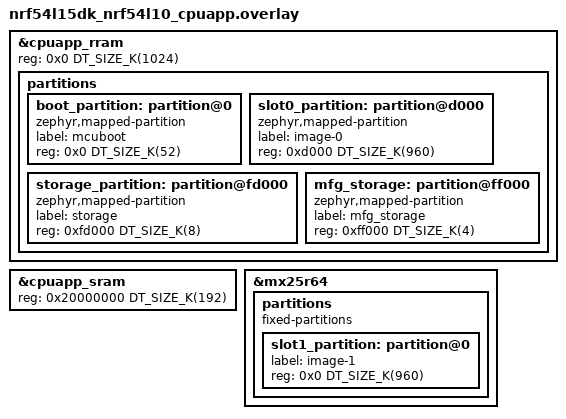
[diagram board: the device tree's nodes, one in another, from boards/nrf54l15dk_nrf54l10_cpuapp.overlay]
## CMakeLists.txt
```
#
# Copyright (c) 2022 Nordic Semiconductor ASA
#
# SPDX-License-Identifier: LicenseRef-Nordic-5-Clause
#

cmake_minimum_required(VERSION 3.20.0)

find_package(Zephyr REQUIRED HINTS $ENV{ZEPHYR_BASE})
project(sidewalk_mfg_test)

# add test file
FILE(GLOB app_sources src/*.c)
target_sources(app PRIVATE ${app_sources})
target_include_directories(app PRIVATE .)
target_link_options(app PRIVATE "LINKER:--start-group")
target_link_libraries(app PRIVATE sidewalk_pal)
target_link_options(app PRIVATE "LINKER:--end-group")
```

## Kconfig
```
#
# Copyright (c) 2022 Nordic Semiconductor ASA
#
# SPDX-License-Identifier: LicenseRef-Nordic-5-Clause
#
config SIDEWALK_BUILD
	default y

config SIDEWALK_USE_PREBUILT_LIBRARIES
	default y


config SIDEWALK_MFG_STORAGE
	default y

config SIDEWALK_MFG_ALLOW_WRITE
	default y

config SIDEWALK_TLV
	default y

config SIDEWALK_TLV_FLASH
	default y

config SIDEWALK_TLV_RAM
	default y

config SIDEWALK_LOG
	default y
	imply LOG

config SIDEWALK_LOG_LEVEL
	default 0

config SIDEWALK_LOG_MSG_LENGTH_MAX
	default 80


source "Kconfig.zephyr"
source "${ZEPHYR_BASE}/../sidewalk/Kconfig.dependencies"
```

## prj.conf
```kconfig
#
# Copyright (c) 2022 Nordic Semiconductor ASA
#
# SPDX-License-Identifier: LicenseRef-Nordic-5-Clause
#
CONFIG_ZTEST=y
CONFIG_MAIN_THREAD_PRIORITY=14
CONFIG_PARTITION_MANAGER_ENABLED=n
```

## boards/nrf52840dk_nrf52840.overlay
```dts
/*
 * Copyright (c) 2024 Nordic Semiconductor ASA
 *
 * SPDX-License-Identifier: LicenseRef-Nordic-5-Clause
 */

#include <state_notifier_aliases.dtsi>

#include <nrf52840_partitions.dtsi>
```

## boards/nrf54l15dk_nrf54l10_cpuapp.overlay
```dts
/*
 * Copyright (c) 2024 Nordic Semiconductor ASA
 *
 * SPDX-License-Identifier: LicenseRef-Nordic-5-Clause
 */

&cpuapp_rram {
	reg = <0x0 DT_SIZE_K(1024)>;
};

&cpuapp_sram {
	reg = <0x20000000 DT_SIZE_K(192)>;
	ranges = <0x0 0x20000000 DT_SIZE_K(192)>;
};

&mx25r64 {
	status = "okay";
};

/delete-node/ &boot_partition;
/delete-node/ &slot0_partition;
/delete-node/ &slot1_partition;
/delete-node/ &storage_partition;

&cpuapp_rram {
	partitions {
		ranges;
		#address-cells = <1>;
		#size-cells = <1>;

		boot_partition: partition@0 {
			compatible = "zephyr,mapped-partition";
			label = "mcuboot";
			reg = <0x0 DT_SIZE_K(52)>;
		};

		slot0_partition: partition@d000 {
			compatible = "zephyr,mapped-partition";
			label = "image-0";
			reg = <0xd000 DT_SIZE_K(960)>;
		};

		storage_partition: partition@fd000 {
			compatible = "zephyr,mapped-partition";
			label = "storage";
			reg = <0xfd000 DT_SIZE_K(8)>;
		};

		mfg_storage: partition@ff000 {
			compatible = "zephyr,mapped-partition";
			label = "mfg_storage";
			reg = <0xff000 DT_SIZE_K(4)>;
		};
	};
};

&mx25r64 {
	partitions {
		compatible = "fixed-partitions";
		#address-cells = <1>;
		#size-cells = <1>;

		slot1_partition: partition@0 {
			label = "image-1";
			reg = <0x0 DT_SIZE_K(960)>;
		};
	};
};
```

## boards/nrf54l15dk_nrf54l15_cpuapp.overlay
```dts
/*
 * Copyright (c) 2024 Nordic Semiconductor ASA
 *
 * SPDX-License-Identifier: LicenseRef-Nordic-5-Clause
 */

#include <state_notifier_aliases.dtsi>

#include <nrf54l15_cpuapp_partitions.dtsi>
```

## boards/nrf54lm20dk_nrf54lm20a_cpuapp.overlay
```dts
/*
 * Copyright (c) 2025 Nordic Semiconductor ASA
 *
 * SPDX-License-Identifier: LicenseRef-Nordic-5-Clause
 */

#include <nrf54lm20_cpuapp_partitions.dtsi>
```

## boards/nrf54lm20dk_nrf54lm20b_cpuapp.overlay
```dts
/*
 * Copyright (c) 2025 Nordic Semiconductor ASA
 *
 * SPDX-License-Identifier: LicenseRef-Nordic-5-Clause
 */

#include "nrf54lm20dk_nrf54lm20a_cpuapp.overlay"
```

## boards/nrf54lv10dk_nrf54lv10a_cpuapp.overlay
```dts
/*
 * Copyright (c) 2025 Nordic Semiconductor ASA
 *
 * SPDX-License-Identifier: LicenseRef-Nordic-5-Clause
 */

#include <nrf54lv10_cpuapp_partitions.dtsi>
```

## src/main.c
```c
/*
 * Copyright (c) 2022 Nordic Semiconductor ASA
 *
 * SPDX-License-Identifier: LicenseRef-Nordic-5-Clause
 */

#include <zephyr/ztest.h>

#include <sid_pal_mfg_store_ifc.h>
#include <sid_mfg_storage.h>
#include <sid_error.h>
#include <zephyr/devicetree.h>

#define MFG_STORAGE_NODE DT_NODELABEL(mfg_storage)

#if !DT_NODE_EXISTS(MFG_STORAGE_NODE)
#error "mfg_storage fixed partition must be defined in the board overlay"
#endif

ZTEST(mfg, test_mfg_storage_read_write)
{
	uint8_t write_data[SID_PAL_MFG_STORE_SERIAL_NUM_SIZE] = { 1, 2, 3, 4, 5 };
	uint8_t read_data[SID_PAL_MFG_STORE_SERIAL_NUM_SIZE] = { 0 };

	sid_pal_mfg_store_region_t mfg_store_region = {
		.addr_start = (uintptr_t)DT_REG_ADDR(MFG_STORAGE_NODE),
		.addr_end =
			(uintptr_t)(DT_REG_ADDR(MFG_STORAGE_NODE) + DT_REG_SIZE(MFG_STORAGE_NODE)),
		.app_value_to_offset = NULL
	};
	sid_pal_mfg_store_init(mfg_store_region);

	zassert_ok(sid_pal_mfg_store_erase(), "Failed to erase mfg storage");

	zassert_equal(SID_ERROR_NONE, sid_pal_mfg_store_write(SID_PAL_MFG_STORE_SERIAL_NUM,
							      write_data, sizeof(write_data)));

	zassert_ok(sid_mfg_storage_flush(), "Failed to flush staged mfg data");

	zassert_true(sid_pal_mfg_store_serial_num_get(read_data),
		     "Failed to read serial number back from mfg storage");
	zassert_mem_equal(write_data, read_data, sizeof(write_data),
			  "Read data does not match written data");

	sid_pal_mfg_store_deinit();
}

ZTEST_SUITE(mfg, NULL, NULL, NULL, NULL, NULL);
```
